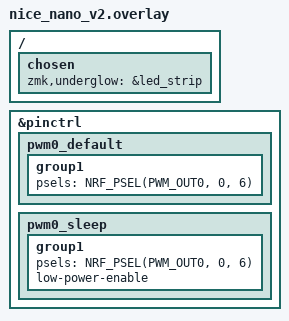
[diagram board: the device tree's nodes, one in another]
#include <dt-bindings/led/led.h>

&pinctrl {
    pwm0_default: pwm0_default {
        group1 {
            psels = <NRF_PSEL(PWM_OUT0, 0, 6)>;
        };
    };
    pwm0_sleep: pwm0_sleep {
        group1 {
            psels = <NRF_PSEL(PWM_OUT0, 0, 6)>;
            low-power-enable;
        };
    };
};




/ {
    chosen {
        zmk,underglow = &led_strip;
    };
};
